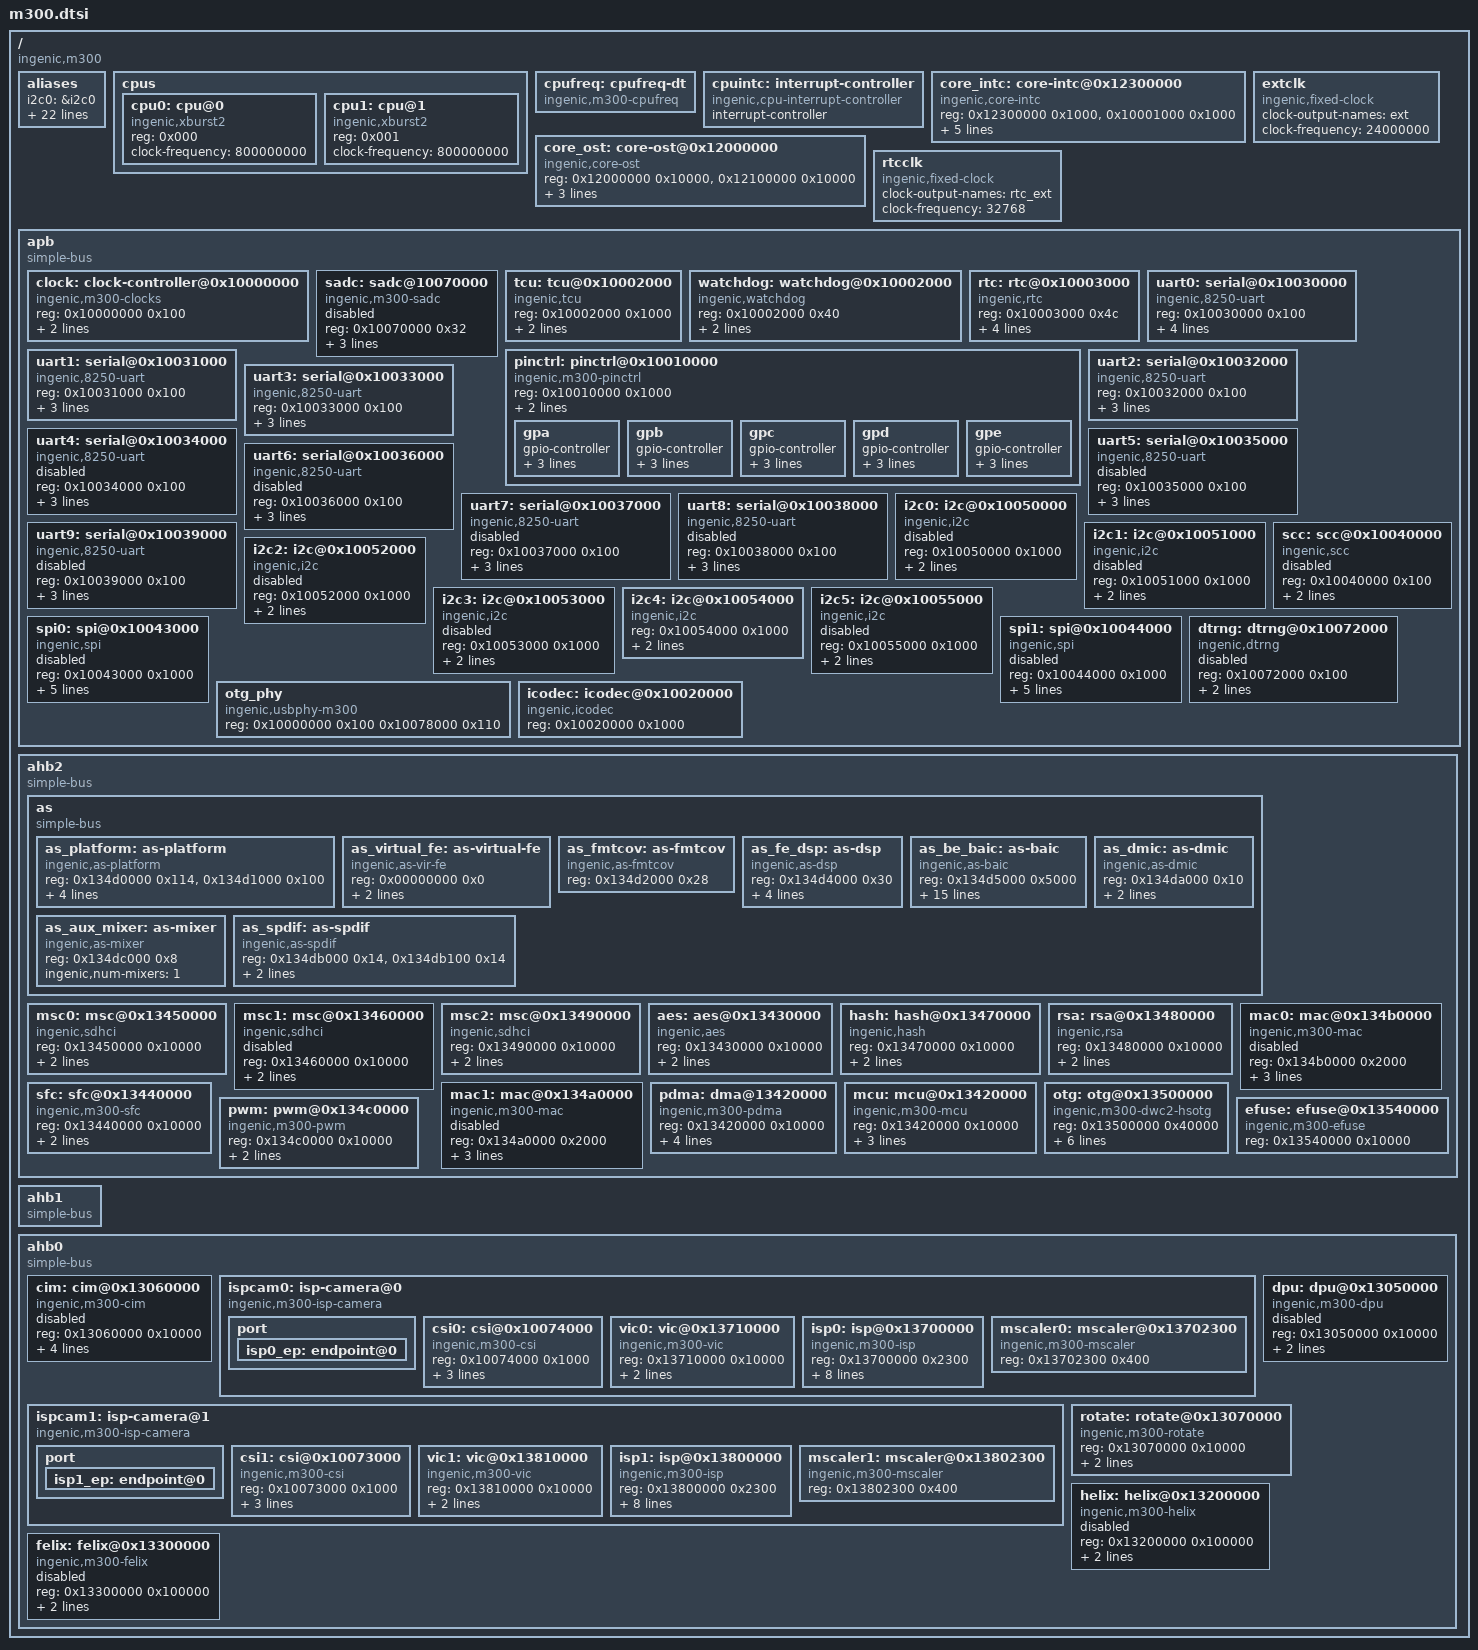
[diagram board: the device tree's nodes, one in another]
#include <dt-bindings/interrupt-controller/m300-irq.h>
#include <dt-bindings/clock/ingenic-tcu.h>
#include <dt-bindings/clock/ingenic-m300.h>
#include <dt-bindings/sound/ingenic-baic.h>
#include <dt-bindings/gpio/ingenic-gpio.h>
#include <dt-bindings/net/ingenic_gmac.h>
#include <dt-bindings/dma/ingenic-pdma.h>

/ {
	#address-cells = <1>;
	#size-cells = <1>;
	compatible = "ingenic,m300";

	aliases: aliases {
		i2c0 = &i2c0;
		i2c1 = &i2c1;
		i2c2 = &i2c2;
		i2c3 = &i2c3;
		i2c4 = &i2c4;
		i2c5 = &i2c5;
		uart0 = &uart0;
		uart1 = &uart1;
		uart2 = &uart2;
		uart3 = &uart3;
		uart4 = &uart4;
		uart5 = &uart5;
		uart6 = &uart6;
		uart7 = &uart7;
		uart8 = &uart8;
		mmc0 = &msc0;
		mmc1 = &msc1;
		mmc2 = &msc2;
		mac0 = &mac0;
		mac1 = &mac1;
		spi0 = &spi0;
		spi1 = &spi1;
		pwm = &pwm;
	};

	cpus: cpus {
		#address-cells = <1>;
		#size-cells = <0>;

		cpu0: cpu@0 {
			device_type = "cpu";
			compatible = "ingenic,xburst2";
			reg = <0x000>;
			clock-frequency = <800000000>;
		};

		cpu1: cpu@1 {
			device_type = "cpu";
			compatible = "ingenic,xburst2";
			reg = <0x001>;
			clock-frequency = <800000000>;
		};
	};

	cpufreq: cpufreq-dt {
		 compatible = "ingenic,m300-cpufreq";
		 status = "okay";
	};

	cpuintc: interrupt-controller {
		#address-cells = <0>;
		#interrupt-cells = <1>;
		interrupt-controller;
		compatible = "ingenic,cpu-interrupt-controller";

	};

	core_intc: core-intc@0x12300000 {
		compatible = "ingenic,core-intc";
		reg = <0x12300000 0x1000>,
		      <0x10001000 0x1000>;
		interrupt-controller;
		#interrupt-cells = <1>;
		cpu-intc-map = <0 0x000>,
			           <1 0x100>,
			           <2 0x200>,
			           <3 0x300>;

		interrupt-parent = <&cpuintc>;
		interrupts = <CORE_INTC_IRQ>;
		interrupt-names ="intc";
	};

	core_ost: core-ost@0x12000000 {
		compatible = "ingenic,core-ost";
		reg = <0x12000000 0x10000>, /*Global ost*/
		      <0x12100000 0x10000>; /*Core ost*/
		interrupt-parent = <&cpuintc>;
		interrupt-names = "sys_ost";
		interrupts = <CORE_SYS_OST_IRQ>;
		cpu-ost-map = 	<0 0x000>,
				<1 0x100>;
	};

	extclk: extclk {
		compatible = "ingenic,fixed-clock";
		clock-output-names ="ext";
		#clock-cells = <0>;
		clock-frequency  = <24000000>;
	};

	rtcclk: rtcclk {
		compatible = "ingenic,fixed-clock";
		clock-output-names ="rtc_ext";
		#clock-cells = <0>;
		clock-frequency = <32768>;
	};

	apb {
		compatible = "simple-bus";
		#address-cells = <1>;
		#size-cells = <1>;
		ranges = <>;

		clock: clock-controller@0x10000000 {
			compatible = "ingenic,m300-clocks";
			reg = <0x10000000 0x100>;
			clocks = <&extclk>, <&rtcclk>;
			clock-names = "ext", "rtc_ext";
			#clock-cells = <1>;
			little-endian;
		};

		sadc: sadc@10070000 {
			compatible = "ingenic,m300-sadc";
			reg = <0x10070000 0x32>;
			interrupt-parent = <&core_intc>;
			interrupts = <IRQ_SADC>;
			interrupt-controller;
			status = "disable";
		};

		tcu: tcu@0x10002000 {
			compatible = "ingenic,tcu";
			reg = <0x10002000 0x1000>;
			interrupt-parent = <&core_intc>;
			interrupt-names = "default";
			interrupts = <IRQ_TCU0>;
			status = "ok";
		};

		watchdog: watchdog@0x10002000 {
			compatible = "ingenic,watchdog";
			reg = <0x10002000 0x40>;
			interrupt-parent = <&core_intc>;
			interrupts = <IRQ_TCU0>;
			status = "ok";
		};

		rtc: rtc@0x10003000 {
			compatible = "ingenic,rtc";
			reg = <0x10003000 0x4c>;
			interrupt-parent = <&core_intc>;
			interrupts = <IRQ_RTC>;
			system-power-controller;
			power-on-press-ms = <1000>;
			status = "ok";
		};

		pinctrl: pinctrl@0x10010000 {
			compatible = "ingenic,m300-pinctrl";
			reg = <0x10010000 0x1000>;
			ingenic,num-chips = <5>;
			ingenic,regs-offset = <0x100>;
			/*ingenic,gpa_voltage = <GPIO_VOLTAGE_3V3>;*/
			/*ingenic,gpe_msc_voltage = <GPIO_VOLTAGE_3V3>;*/

			gpa: gpa {
				gpio-controller;
				#gpio-cells = <3>;
				#ingenic,pincfg-cells = <3>;
				#ingenic,pinmux-cells = <2>;
				interrupts = <IRQ_GPIO0>;
				interrupt-parent = <&core_intc>;
				interrupt-controller;
				#interrupt-cells = <2>;
			};

			gpb: gpb {
				gpio-controller;
				#gpio-cells = <3>;
				#ingenic,pincfg-cells = <3>;
				#ingenic,pinmux-cells = <2>;
				interrupts = <IRQ_GPIO1>;
				interrupt-parent = <&core_intc>;
				interrupt-controller;
				#interrupt-cells = <2>;
			};

			gpc: gpc {
				gpio-controller;
				#gpio-cells = <3>;
				#ingenic,pincfg-cells = <3>;
				#ingenic,pinmux-cells = <2>;
				interrupts = <IRQ_GPIO2>;
				interrupt-parent = <&core_intc>;
				interrupt-controller;
				#interrupt-cells = <2>;
			};

			gpd: gpd {
				gpio-controller;
				#gpio-cells = <3>;
				#ingenic,pincfg-cells = <3>;
				#ingenic,pinmux-cells = <2>;
				interrupts = <IRQ_GPIO3>;
				interrupt-parent = <&core_intc>;
				interrupt-controller;
				#interrupt-cells = <2>;
			};

			gpe: gpe {
				gpio-controller;
				#gpio-cells = <3>;
				#ingenic,pincfg-cells = <3>;
				#ingenic,pinmux-cells = <2>;
				interrupts = <IRQ_GPIO4>;
				interrupt-parent = <&core_intc>;
				interrupt-controller;
				#interrupt-cells = <2>;
			};

		};

		uart0: serial@0x10030000 {
			compatible = "ingenic,8250-uart";
			reg = <0x10030000 0x100>;
			reg-shift = <2>;
			interrupt-parent = <&core_intc>;
			interrupts = <IRQ_UART0>;
			clocks = <&extclk 0>;
			clock-names = "uart0";
		};
		uart1: serial@0x10031000 {
			compatible = "ingenic,8250-uart";
			reg = <0x10031000 0x100>;
			reg-shift = <2>;
			interrupt-parent = <&core_intc>;
			interrupts = <IRQ_UART1>;
		};
		uart2: serial@0x10032000 {
			compatible = "ingenic,8250-uart";
			reg = <0x10032000 0x100>;
			reg-shift = <2>;
			interrupt-parent = <&core_intc>;
			interrupts = <IRQ_UART2>;
		};
		uart3: serial@0x10033000 {
			compatible = "ingenic,8250-uart";
			reg = <0x10033000 0x100>;
			reg-shift = <2>;
			interrupt-parent = <&core_intc>;
			interrupts = <IRQ_UART3>;
		};

		uart4: serial@0x10034000 {
			compatible = "ingenic,8250-uart";
			reg = <0x10034000 0x100>;
			reg-shift = <2>;
			interrupt-parent = <&core_intc>;
			interrupts = <IRQ_UART4>;
			status = "disabled";
		};
		uart5: serial@0x10035000 {
			compatible = "ingenic,8250-uart";
			reg = <0x10035000 0x100>;
			reg-shift = <2>;
			interrupt-parent = <&core_intc>;
			interrupts = <IRQ_UART5>;
			status = "disabled";
		};
		uart6: serial@0x10036000 {
			compatible = "ingenic,8250-uart";
			reg = <0x10036000 0x100>;
			reg-shift = <2>;
			interrupt-parent = <&core_intc>;
			interrupts = <IRQ_UART6>;
			status = "disabled";
		};
		uart7: serial@0x10037000 {
			compatible = "ingenic,8250-uart";
			reg = <0x10037000 0x100>;
			reg-shift = <2>;
			interrupt-parent = <&core_intc>;
			interrupts = <IRQ_UART7>;
			status = "disabled";
		};

		uart8: serial@0x10038000 {
			compatible = "ingenic,8250-uart";
			reg = <0x10038000 0x100>;
			reg-shift = <2>;
			interrupt-parent = <&core_intc>;
			interrupts = <IRQ_UART8>;
			status = "disabled";
		};
		uart9: serial@0x10039000 {
			compatible = "ingenic,8250-uart";
			reg = <0x10039000 0x100>;
			reg-shift = <2>;
			interrupt-parent = <&core_intc>;
			interrupts = <IRQ_UART9>;
			status = "disabled";
		};

		i2c0: i2c@0x10050000 {
			compatible = "ingenic,i2c";
			reg = <0x10050000 0x1000>;
			interrupt-parent = <&core_intc>;
			interrupts = <IRQ_I2C0>;
			#address-cells = <1>;
			#size-cells = <0>;
			status = "disable";
		};

		i2c1: i2c@0x10051000 {
			compatible = "ingenic,i2c";
			reg = <0x10051000 0x1000>;
			interrupt-parent = <&core_intc>;
			interrupts = <IRQ_I2C1>;
			#address-cells = <1>;
			#size-cells = <0>;
			status = "disabled";
		};

		i2c2: i2c@0x10052000 {
			compatible = "ingenic,i2c";
			reg = <0x10052000 0x1000>;
			interrupt-parent = <&core_intc>;
			interrupts = <IRQ_I2C2>;
			#address-cells = <1>;
			#size-cells = <0>;
			status = "disabled";
		};

		i2c3: i2c@0x10053000 {
			compatible = "ingenic,i2c";
			reg = <0x10053000 0x1000>;
			interrupt-parent = <&core_intc>;
			interrupts = <IRQ_I2C3>;
			#address-cells = <1>;
			#size-cells = <0>;
			status = "disabled";
		};

		i2c4: i2c@0x10054000 {
			compatible = "ingenic,i2c";
			reg = <0x10054000 0x1000>;
			interrupt-parent = <&core_intc>;
			interrupts = <IRQ_I2C4>;
			#address-cells = <1>;
			#size-cells = <0>;
			status = "okay";
		};

		i2c5: i2c@0x10055000 {
			compatible = "ingenic,i2c";
			reg = <0x10055000 0x1000>;
			interrupt-parent = <&core_intc>;
			interrupts = <IRQ_I2C5>;
			#address-cells = <1>;
			#size-cells = <0>;
			status = "disabled";
		};

		spi0: spi@0x10043000 {
			compatible = "ingenic,spi";
			reg = <0x10043000 0x1000>;
			interrupt-parent = <&core_intc>;
			interrupts = <IRQ_SSI0>;
			dmas = <&pdma INGENIC_DMA_TYPE(INGENIC_DMA_REQ_SSI0_TX)>,
				   <&pdma INGENIC_DMA_TYPE(INGENIC_DMA_REQ_SSI0_RX)>;
			dma-names = "tx", "rx";
			#address-cells = <1>;
			#size-cells = <0>;
			status = "disabled";
		};

		spi1: spi@0x10044000 {
			compatible = "ingenic,spi";
			reg = <0x10044000 0x1000>;
			interrupt-parent = <&core_intc>;
			interrupts = <IRQ_SSI1>;
			dmas = <&pdma INGENIC_DMA_TYPE(INGENIC_DMA_REQ_SSI1_TX)>,
				   <&pdma INGENIC_DMA_TYPE(INGENIC_DMA_REQ_SSI1_RX)>;
			dma-names = "tx", "rx";
			#address-cells = <1>;
			#size-cells = <0>;
			status = "disabled";
		};

		scc: scc@0x10040000 {
			compatible = "ingenic,scc";
			reg = <0x10040000 0x100>;
			interrupt-parent = <&core_intc>;
			interrupts = <IRQ_SCC>;
			status = "disabled";
		};

		dtrng: dtrng@0x10072000 {
			compatible = "ingenic,dtrng";
			reg = <0x10072000 0x100>;
			interrupt-parent = <&core_intc>;
			interrupts = <IRQ_DTRNG>;
			status = "enable";
		};

		otg_phy: otg_phy {
			#address-cells = <1>;
			#size-cells = <1>;
			compatible = "ingenic,usbphy-m300";
			reg = <0x10000000 0x100 0x10078000 0x110>;
			#phy-cells = <0>;

		};

		icodec: icodec@0x10020000 {
			compatible = "ingenic,icodec";
			reg = <0x10020000 0x1000>;
			status = "okay";
		};
	};

	ahb2 {
		compatible = "simple-bus";
		#address-cells = <1>;
		#size-cells = <1>;
		ranges = <>;

		as:as {
			compatible = "simple-bus";
			#address-cells = <1>;
			#size-cells = <1>;
			ranges = <>;

			as_platform: as-platform {
				compatible = "ingenic,as-platform";
				reg = <0x134d0000 0x114>, <0x134d1000 0x100>;
				reg-names = "dma", "fifo";
				ingenic,fifo-size = <4096>;
				interrupt-parent = <&core_intc>;
				interrupts = <IRQ_AUDIO>;
				ingenic,fth_quirk;
			};
			as_virtual_fe: as-virtual-fe {
				compatible = "ingenic,as-vir-fe";
				reg = <0x00000000 0x0>;
				ingenic,cap-dai-bm = <0xc>;
				ingenic,num-dais = <4>;
			};
			as_fmtcov: as-fmtcov {
				compatible = "ingenic,as-fmtcov";
				reg = <0x134d2000 0x28>;
			};
			as_fe_dsp: as-dsp {
				compatible = "ingenic,as-dsp";
				reg = <0x134d4000 0x30>;
				ingenic,li-port = <0 1 2 3 4 6 7 8 9 10 11 12>;
				ingenic,lo-port = <0 1 2 3 4 5 6 7 8 9 10 11>;
				ingenic,cap-dai-bm = <0x3e0>;
				ingenic,num-dais = <10>;
			};
			as_be_baic: as-baic {
				compatible = "ingenic,as-baic";
				reg = <0x134d5000 0x5000>;
				ingenic,num-dais = <5>;
				/* using dai-array to determine which BAIC to use */
				ingenic,dai-array = <0>, <1>, <2>, <3>, <4>;
				ingenic,dai-mode = <BAIC_3AND(BAIC_PCM_MODE, BAIC_DSP_MODE, BAIC_I2S_MODE)>,
					<BAIC_3AND(BAIC_PCM_MODE, BAIC_DSP_MODE, BAIC_I2S_MODE)>,
					<BAIC_4AND(BAIC_I2S_MODE, BAIC_TDM1_MODE, BAIC_TDM2_MODE, BAIC_NO_REPLAY)>,
					<BAIC_4AND(BAIC_I2S_MODE, BAIC_TDM1_MODE, BAIC_TDM2_MODE, BAIC_NO_RECORD)>,
					<BAIC_3AND(BAIC_PCM_MODE, BAIC_DSP_MODE, BAIC_I2S_MODE)>;
				ingenic,data-pin-num = <1>, <1>, <4>, <4>, <1>;
				ingenic,clk-split = <1>, <1>, <1>, <1>, <0>;
				ingenic,clk-rname = "div_i2s0","div_i2s0","div_i2s2","no_clk","mux_pcm";
				ingenic,clk-tname = "div_i2s1","div_i2s1","no_clk","div_i2s3","mux_pcm";
				ingenic,pcm-clk-parent = "div_i2s2";
			};
			as_dmic: as-dmic {
				compatible = "ingenic,as-dmic";
				reg = <0x134da000 0x10>;
				ingenic,clk-name = "mux_dmic";
				ingenic,clk-parent = "ext";
			};

			as_aux_mixer: as-mixer {
				compatible = "ingenic,as-mixer";
				reg = <0x134dc000 0x8>;
				ingenic,num-mixers = <1>;
			};
			as_spdif: as-spdif {
				compatible = "ingenic,as-spdif";
				reg = <0x134db000 0x14>, <0x134db100 0x14>;
				reg-names = "out", "in";
				ingenic,clk-name = "mux_spdif";
				ingenic,clk-parent = "div_i2s2";
			};
		};

		msc0: msc@0x13450000 {
			compatible = "ingenic,sdhci";
			reg = <0x13450000 0x10000>;
			interrupt-parent = <&core_intc>;
			interrupts = <IRQ_MSC0>;
		};

		msc1: msc@0x13460000 {
			compatible = "ingenic,sdhci";
			reg = <0x13460000 0x10000>;
			status = "disabled";
			interrupt-parent = <&core_intc>;
			interrupts = <IRQ_MSC1>;
		};

		msc2: msc@0x13490000 {
			compatible = "ingenic,sdhci";
			reg = <0x13490000 0x10000>;
			interrupt-parent = <&core_intc>;
			interrupts = <IRQ_MSC2>;
		};

		aes: aes@0x13430000 {
			compatible = "ingenic,aes";
			reg = <0x13430000 0x10000>;
			interrupt-parent = <&core_intc>;
			interrupts = <IRQ_AES>;
			status = "ok";
		};

		hash: hash@0x13470000 {
			compatible = "ingenic,hash";
			reg = <0x13470000 0x10000>;
			interrupt-parent = <&core_intc>;
			interrupts = <IRQ_HASH>;
			status = "ok";
		};

		rsa: rsa@0x13480000 {
			compatible = "ingenic,rsa";
			reg = <0x13480000 0x10000>;
			interrupt-parent = <&core_intc>;
			interrupts = <IRQ_RSA>;
			status = "ok";
		};

		mac0: mac@0x134b0000 {
			compatible = "ingenic,m300-mac";
			reg = <0x134b0000 0x2000>;
			interrupt-parent = <&core_intc>;
			interrupts = <IRQ_GMAC0>;
			status = "disabled";
			ingenic,rst-ms = <10>;
		};

		mac1: mac@0x134a0000 {
			compatible = "ingenic,m300-mac";
			reg = <0x134a0000 0x2000>;
			interrupt-parent = <&core_intc>;
			interrupts = <IRQ_GMAC1>;
			status = "disabled";
			ingenic,rst-ms = <10>;
		};

		sfc: sfc@0x13440000 {
			compatible = "ingenic,m300-sfc";
			reg = <0x13440000 0x10000>;
			interrupt-parent = <&core_intc>;
			interrupts = <IRQ_SFC>;
		};

		pdma: dma@13420000 {
			compatible = "ingenic,m300-pdma";
			reg = <0x13420000 0x10000>;
			interrupt-parent = <&core_intc>;
			interrupt-names = "pdma", "pdmad";
			interrupts = <IRQ_PDMA>, <IRQ_PDMAD>;
			#dma-channels = <32>;
			#dma-cells = <1>;
			ingenic,reserved-chs = <0x3>;
		};

		mcu: mcu@0x13420000 {
			compatible = "ingenic,m300-mcu";
			reg = <0x13420000 0x10000>;
			interrupt-parent = <&core_intc>;
			interrupt-names = "pdmam";
			interrupts = <IRQ_PDMAM>;
			ingenic,tcsm_size = <16384>;
		};

		pwm: pwm@0x134c0000 {
			compatible = "ingenic,m300-pwm";
			reg = <0x134c0000 0x10000>;
			interrupt-parent = <&core_intc>;
			interrupts = <IRQ_PWM>;
		};

		otg: otg@0x13500000 {
			compatible = "ingenic,m300-dwc2-hsotg";
			reg = <0x13500000 0x40000>;
			interrupt-parent = <&core_intc>;
			interrupts = <IRQ_OTG>;
			ingenic,usbphy=<&otg_phy>;

			g-rx-fifo-size = <1096>;
			g-np-tx-fifo-size = <512>;
			g-tx-fifo-size = <16 16 16 128 256 256 512 768>;
			status = "okay";
		};

		efuse: efuse@0x13540000 {
			compatible = "ingenic,m300-efuse";
			reg = <0x13540000 0x10000>;
			status = "okay";
		};
	};

	ahb1 {
		compatible = "simple-bus";
		#address-cells = <1>;
		#size-cells = <1>;
		ranges = <>;

	};

	ahb0 {
		compatible = "simple-bus";
		#address-cells = <1>;
		#size-cells = <1>;
		ranges = <>;

		cim: cim@0x13060000 {
			compatible = "ingenic,m300-cim";
			reg = <0x13060000 0x10000>;
			interrupt-parent = <&core_intc>;
			interrupts = <IRQ_CIM>;
			clocks = <&clock CLK_DIV_CIM>, <&clock CLK_GATE_CIM>, <&clock CLK_GATE_MIPI_CSI>;
			clock-names = "div_cim", "gate_cim", "gate_mipi";
			status = "disable";
		};

		ispcam0: isp-camera@0 {
			compatible = "ingenic,m300-isp-camera";
			#address-cells = <1>;
			#size-cells = <1>;
			ranges = <>;

			port {
				isp0_ep:endpoint@0 {

				};
			};


			csi0: csi@0x10074000 {
				compatible = "ingenic,m300-csi";
				reg = <0x10074000 0x1000>;
				interrupt-parent = <&core_intc>;
				interrupts = <IRQ_MIPI_CSI_4>;	// 4lane csi
				clocks = <&clock CLK_GATE_MIPI_CSI>;
				clock-names = "gate_csi";
			};

			vic0: vic@0x13710000 {
				compatible = "ingenic,m300-vic";
				reg = <0x13710000 0x10000>;
				interrupt-parent = <&core_intc>;
				interrupts = <IRQ_VIC0>;
				status = "ok";
			};
			isp0: isp@0x13700000 {
				compatible = "ingenic,m300-isp";
				reg = <0x13700000 0x2300>;
				interrupt-parent = <&core_intc>;
				interrupts = <IRQ_ISP0>;
				clocks = <&clock CLK_DIV_ISP>, <&clock CLK_GATE_ISP0> , <&clock POWER_ISP0>;
				clock-names = "div_isp", "gate_isp0", "power_isp0";
				status = "ok";
				ingenic,cpm_reset = <0xb00000c4>;
				ingenic,bit_sr = <25>;
				ingenic,bit_stp = <24>;
				ingenic,bit_ack = <23>;
			};

			mscaler0: mscaler@0x13702300 {
				compatible = "ingenic,m300-mscaler";
				reg = <0x13702300 0x400>;
				status = "ok";
			};


		};
		ispcam1: isp-camera@1 {
			compatible = "ingenic,m300-isp-camera";
			#address-cells = <1>;
			#size-cells = <1>;
			ranges = <>;

			port {
				isp1_ep:endpoint@0 {

				};
			};


			csi1: csi@0x10073000 {
				compatible = "ingenic,m300-csi";
				reg = <0x10073000 0x1000>;
				interrupt-parent = <&core_intc>;
				interrupts = <IRQ_MIPI_CSI2>;	// 2lane csi
				clocks = <&clock CLK_GATE_MIPI_CSI>;
				clock-names = "gate_csi";
			};

			vic1: vic@0x13810000 {
				compatible = "ingenic,m300-vic";
				reg = <0x13810000 0x10000>;
				interrupt-parent = <&core_intc>;
				interrupts = <IRQ_VIC1>;
				status = "ok";
			};

			isp1: isp@0x13800000 {
				compatible = "ingenic,m300-isp";
				reg = <0x13800000 0x2300>;
				interrupt-parent = <&core_intc>;
				interrupts = <IRQ_ISP1>;
				clocks = <&clock CLK_DIV_ISP>, <&clock CLK_GATE_ISP1>, <&clock POWER_ISP1>;
				clock-names = "div_isp", "gate_isp1", "power_isp1";
				status = "ok";
				ingenic,cpm_reset = <0xb00000c4>;
				ingenic,bit_sr = <22>;
				ingenic,bit_stp = <21>;
				ingenic,bit_ack = <20>;
			};

			mscaler1: mscaler@0x13802300 {
				compatible = "ingenic,m300-mscaler";
				reg = <0x13802300 0x400>;
				status = "ok";
			};
		};

		dpu: dpu@0x13050000 {
			compatible = "ingenic,m300-dpu";
			reg = <0x13050000 0x10000>;
			interrupt-parent = <&core_intc>;
			interrupts = <IRQ_LCD>;
			status = "disabled";
		};

		rotate: rotate@0x13070000 {
			compatible = "ingenic,m300-rotate";
			reg = <0x13070000 0x10000>;
			interrupt-parent = <&core_intc>;
			interrupts = <IRQ_ROTATE>;
			status = "okay";
		};

		helix: helix@0x13200000 {
			compatible = "ingenic,m300-helix";
			reg = <0x13200000 0x100000>;
			interrupt-parent = <&core_intc>;
			interrupts = <IRQ_HELIX>;
			status = "disabled";
		};

		felix: felix@0x13300000 {
			compatible = "ingenic,m300-felix";
			reg = <0x13300000 0x100000>;
			interrupt-parent = <&core_intc>;
			interrupts = <IRQ_FELIX>;
			status = "disabled";
		};

	};

};
#include "m300-pinctrl.dtsi"
